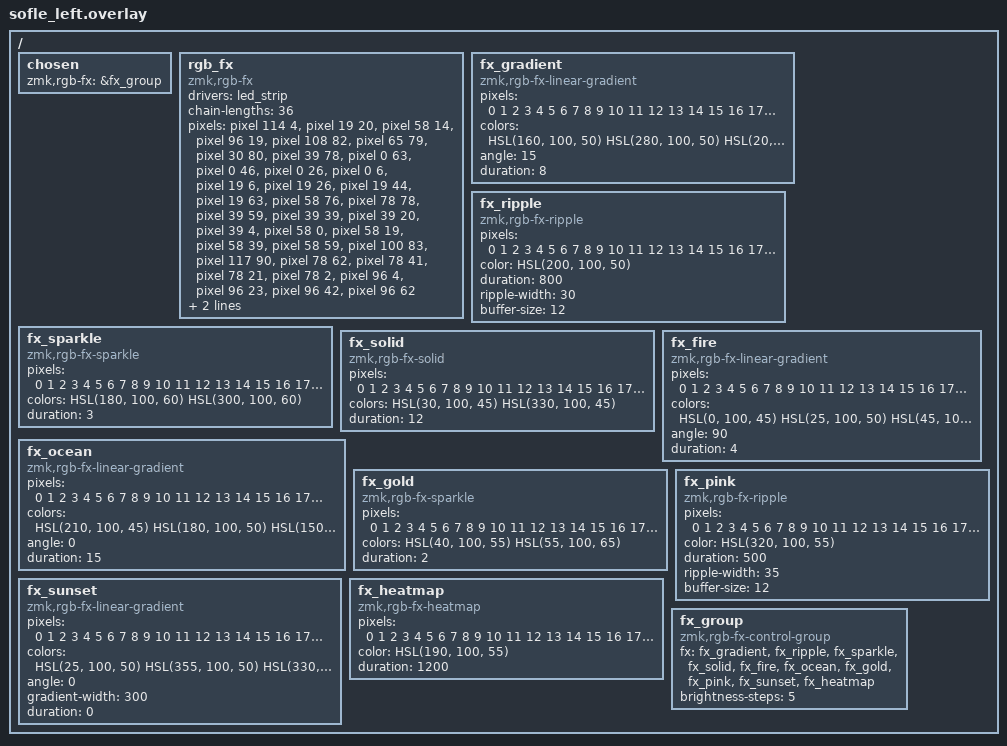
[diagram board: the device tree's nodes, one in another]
/*
 * RGB FX - left half (Sofle MX, 36 LEDs).
 *
 * Chain order (from the PCB photo, josefadamcik Sofle RGB v4):
 *   LED 1  = encoder indicator
 *   LED 2-7  = underglow (drop lighting)
 *   LED 8-36 = per-key (underlighting)
 * pixel index i in this array = chain position (LED i+1).
 *
 * Coordinates use the continuous canvas, hardware-confirmed orientation:
 * left half x 0 (outer/pinky) to 117 (inner edge), y 0 (top) to 90
 * (bottom). The original map read from the PCB photo (back side) was
 * mirrored; x was flipped (x' = 117 - x) after verifying the real
 * orientation on hardware with the BT panel indicator.
 *
 * key-pixels: pixel index for each of the 60 positions of the Sofle
 * matrix transform (rows of 12/12/12/14/10; row 4 includes both encoder
 * clicks). The OTHER half's positions point to the pixel on the inner
 * edge of their row so ripples from remote keys enter from the seam.
 */

#include <rgb_fx.dtsi>
#include <dt-bindings/zmk/rgb_fx.h>

/ {
    chosen {
        zmk,rgb-fx = &fx_group;
    };

    rgb_fx: rgb_fx {
        compatible = "zmk,rgb-fx";
        drivers = <&led_strip>;
        chain-lengths = <36>;
        pixels
            = <&pixel 114 4>, /*  0 = LED#1 encoder indicator (inner) */
              <&pixel 19 20>, /*  1 = LED#2 underglow 1 */
              <&pixel 58 14>, /*  2 = LED#3 underglow 2 */
              <&pixel 96 19>, /*  3 = LED#4 underglow 3 */
              <&pixel 108 82>, /*  4 = LED#5 underglow 4 */
              <&pixel 65 79>, /*  5 = LED#6 underglow 5 */
              <&pixel 30 80>, /*  6 = LED#7 underglow 6 */
              <&pixel 39 78>, /*  7 = LED#8 thumb GUI (outermost) */
              <&pixel 0 63>, /*  8 = LED#9 pinky col row3 */
              <&pixel 0 46>, /*  9 = LED#10 pinky col row2 */
              <&pixel 0 26>, /* 10 = LED#11 pinky col row1 */
              <&pixel 0 6>, /* 11 = LED#12 pinky col row0 (BT_CLR) */
              <&pixel 19 6>, /* 12 = LED#13 col1 row0 */
              <&pixel 19 26>, /* 13 = LED#14 col1 row1 */
              <&pixel 19 44>, /* 14 = LED#15 col1 row2 */
              <&pixel 19 63>, /* 15 = LED#16 col1 row3 */
              <&pixel 58 76>, /* 16 = LED#17 thumb ALT */
              <&pixel 78 78>, /* 17 = LED#18 thumb CTRL */
              <&pixel 39 59>, /* 18 = LED#19 col2 row3 */
              <&pixel 39 39>, /* 19 = LED#20 col2 row2 */
              <&pixel 39 20>, /* 20 = LED#21 col2 row1 */
              <&pixel 39 4>, /* 21 = LED#22 col2 row0 */
              <&pixel 58 0>, /* 22 = LED#23 col3 row0 */
              <&pixel 58 19>, /* 23 = LED#24 col3 row1 */
              <&pixel 58 39>, /* 24 = LED#25 col3 row2 */
              <&pixel 58 59>, /* 25 = LED#26 col3 row3 */
              <&pixel 100 83>, /* 26 = LED#27 thumb LOWER */
              <&pixel 117 90>, /* 27 = LED#28 thumb ENTER (innermost) */
              <&pixel 78 62>, /* 28 = LED#29 col4 row3 */
              <&pixel 78 41>, /* 29 = LED#30 col4 row2 */
              <&pixel 78 21>, /* 30 = LED#31 col4 row1 */
              <&pixel 78 2>, /* 31 = LED#32 col4 row0 */
              <&pixel 96 4>, /* 32 = LED#33 inner col row0 */
              <&pixel 96 23>, /* 33 = LED#34 inner col row1 */
              <&pixel 96 42>, /* 34 = LED#35 inner col row2 */
              <&pixel 96 62>; /* 35 = LED#36 inner col row3 */
        key-pixels
            = <11 12 21 22 31 32 32 32 32 32 32 32
               10 13 20 23 30 33 33 33 33 33 33 33
                9 14 19 24 29 34 34 34 34 34 34 34
                8 15 18 25 28 35  0 35 35 35 35 35 35 35
                7 16 17 26 27 27 27 27 27 27>;
    };

    fx_gradient: fx_gradient {
        compatible = "zmk,rgb-fx-linear-gradient";
        pixels = <0 1 2 3 4 5 6 7 8 9 10 11 12 13 14 15 16 17 18 19 20 21 22 23 24 25 26 27 28 29 30 31 32 33 34 35>;
        colors = <HSL(160, 100, 50) HSL(280, 100, 50) HSL(20, 100, 50)>;
        angle = <15>;
        duration = <8>;
    };

    fx_ripple: fx_ripple {
        compatible = "zmk,rgb-fx-ripple";
        pixels = <0 1 2 3 4 5 6 7 8 9 10 11 12 13 14 15 16 17 18 19 20 21 22 23 24 25 26 27 28 29 30 31 32 33 34 35>;
        color = <HSL(200, 100, 50)>;
        duration = <800>;
        ripple-width = <30>;
        buffer-size = <12>;
    };

    fx_sparkle: fx_sparkle {
        compatible = "zmk,rgb-fx-sparkle";
        pixels = <0 1 2 3 4 5 6 7 8 9 10 11 12 13 14 15 16 17 18 19 20 21 22 23 24 25 26 27 28 29 30 31 32 33 34 35>;
        colors = <HSL(180, 100, 60) HSL(300, 100, 60)>;
        duration = <3>;
    };

    fx_solid: fx_solid {
        compatible = "zmk,rgb-fx-solid";
        pixels = <0 1 2 3 4 5 6 7 8 9 10 11 12 13 14 15 16 17 18 19 20 21 22 23 24 25 26 27 28 29 30 31 32 33 34 35>;
        colors = <HSL(30, 100, 45) HSL(330, 100, 45)>;
        duration = <12>;
    };


    fx_fire: fx_fire {
        compatible = "zmk,rgb-fx-linear-gradient";
        pixels = <0 1 2 3 4 5 6 7 8 9 10 11 12 13 14 15 16 17 18 19 20 21 22 23 24 25 26 27 28 29 30 31 32 33 34 35>;
        colors = <HSL(0, 100, 45) HSL(25, 100, 50) HSL(45, 100, 55)>;
        angle = <90>;
        duration = <4>;
    };

    fx_ocean: fx_ocean {
        compatible = "zmk,rgb-fx-linear-gradient";
        pixels = <0 1 2 3 4 5 6 7 8 9 10 11 12 13 14 15 16 17 18 19 20 21 22 23 24 25 26 27 28 29 30 31 32 33 34 35>;
        colors = <HSL(210, 100, 45) HSL(180, 100, 50) HSL(150, 90, 45)>;
        angle = <0>;
        duration = <15>;
    };

    fx_gold: fx_gold {
        compatible = "zmk,rgb-fx-sparkle";
        pixels = <0 1 2 3 4 5 6 7 8 9 10 11 12 13 14 15 16 17 18 19 20 21 22 23 24 25 26 27 28 29 30 31 32 33 34 35>;
        colors = <HSL(40, 100, 55) HSL(55, 100, 65)>;
        duration = <2>;
    };

    fx_pink: fx_pink {
        compatible = "zmk,rgb-fx-ripple";
        pixels = <0 1 2 3 4 5 6 7 8 9 10 11 12 13 14 15 16 17 18 19 20 21 22 23 24 25 26 27 28 29 30 31 32 33 34 35>;
        color = <HSL(320, 100, 55)>;
        duration = <500>;
        ripple-width = <35>;
        buffer-size = <12>;
    };

    fx_sunset: fx_sunset {
        compatible = "zmk,rgb-fx-linear-gradient";
        pixels = <0 1 2 3 4 5 6 7 8 9 10 11 12 13 14 15 16 17 18 19 20 21 22 23 24 25 26 27 28 29 30 31 32 33 34 35>;
        colors = <HSL(25, 100, 50) HSL(355, 100, 50) HSL(330, 100, 50)
                  HSL(285, 100, 50) HSL(235, 100, 50)>;
        angle = <0>;
        gradient-width = <300>;
        duration = <0>;
    };

    fx_heatmap: fx_heatmap {
        compatible = "zmk,rgb-fx-heatmap";
        pixels = <0 1 2 3 4 5 6 7 8 9 10 11 12 13 14 15 16 17 18 19 20 21 22 23 24 25 26 27 28 29 30 31 32 33 34 35>;
        color = <HSL(190, 100, 55)>;
        duration = <1200>;
    };

    fx_group: fx_group {
        compatible = "zmk,rgb-fx-control-group";
        fx = <&fx_gradient &fx_ripple &fx_sparkle &fx_solid
              &fx_fire &fx_ocean &fx_gold &fx_pink &fx_sunset &fx_heatmap>;
        brightness-steps = <5>;
    };
};
